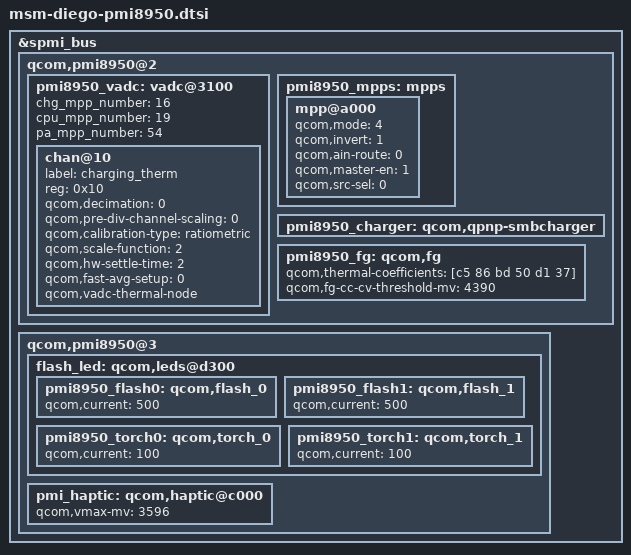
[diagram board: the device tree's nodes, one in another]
&spmi_bus {

	qcom,pmi8950@2 {
		pmi8950_vadc: vadc@3100 {
			chg_mpp_number = <16>;
			cpu_mpp_number = <19>;
			pa_mpp_number = <54>;
			chan@10 {
				label = "charging_therm";
				reg = <0x10>;
				qcom,decimation = <0>;
				qcom,pre-div-channel-scaling = <0>;
				qcom,calibration-type = "ratiometric";
				qcom,scale-function = <2>;
				qcom,hw-settle-time = <2>;
				qcom,fast-avg-setup = <0>;
				qcom,vadc-thermal-node;
			};
		};

		pmi8950_mpps: mpps {
			mpp@a000 {
				/delete-property/ status;
				qcom,mode = <4>; /* AIN input */
				qcom,invert = <1>; /* Invert the signal of the gpio */
				qcom,ain-route = <0>; /* AMUX 0x10 */
				qcom,master-en = <1>; /* Enable the pin block */
				qcom,src-sel = <0>; /* Function constant */
			};
		};

		pmi8950_charger: qcom,qpnp-smbcharger {
			/delete-property/ qcom,parallel-usb-min-current-ma;
			/delete-property/ qcom,parallel-usb-9v-min-current-ma;
			/delete-property/ qcom,parallel-allowed-lowering-ma;
		};

		pmi8950_fg: qcom,fg {
			qcom,thermal-coefficients = [c5 86 bd 50 d1 37];
	                qcom,fg-cc-cv-threshold-mv = <4390>;
		};
	};

	qcom,pmi8950@3 {
		flash_led: qcom,leds@d300 {
			pmi8950_flash0: qcom,flash_0 {
				qcom,current = <500>;
			};

			pmi8950_flash1: qcom,flash_1 {
				qcom,current = <500>;
			};

			pmi8950_torch0: qcom,torch_0 {
				qcom,current = <100>;
			};

			pmi8950_torch1: qcom,torch_1 {
				qcom,current = <100>;
			};
		};

		pmi_haptic: qcom,haptic@c000 {
			qcom,vmax-mv = <3596>;
			/delete-property/ qcom,en-brake;
		};
	};
};
